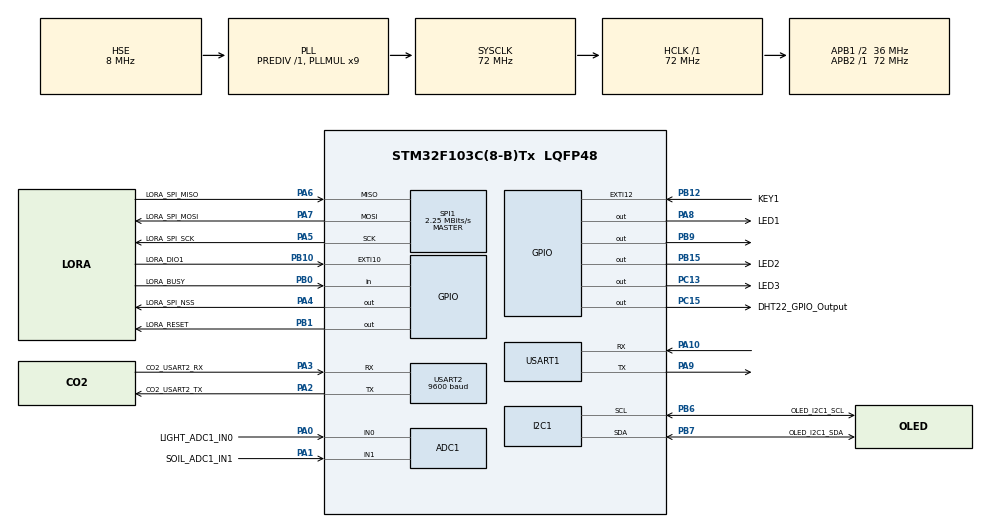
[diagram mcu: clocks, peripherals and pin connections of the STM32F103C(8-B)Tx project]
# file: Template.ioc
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ADC1.Channel-0\#ChannelRegularConversion=ADC_CHANNEL_0
ADC1.Channel-1\#ChannelRegularConversion=ADC_CHANNEL_1
ADC1.ContinuousConvMode=ENABLE
ADC1.NbrOfConversion=2
ADC1.NbrOfConversionFlag=1
ADC1.Rank-0\#ChannelRegularConversion=1
ADC1.Rank-1\#ChannelRegularConversion=2
ADC1.SamplingTime-0\#ChannelRegularConversion=ADC_SAMPLETIME_28CYCLES_5
ADC1.SamplingTime-1\#ChannelRegularConversion=ADC_SAMPLETIME_28CYCLES_5
ADC1.master=1
Dma.ADC1.0.Direction=DMA_PERIPH_TO_MEMORY
Dma.ADC1.0.Instance=DMA1_Channel1
Dma.ADC1.0.MemDataAlignment=DMA_MDATAALIGN_HALFWORD
Dma.ADC1.0.MemInc=DMA_MINC_ENABLE
Dma.ADC1.0.Mode=DMA_CIRCULAR
Dma.ADC1.0.PeriphDataAlignment=DMA_PDATAALIGN_HALFWORD
Dma.ADC1.0.PeriphInc=DMA_PINC_DISABLE
Dma.ADC1.0.Priority=DMA_PRIORITY_LOW
Dma.Request0=ADC1
Mcu.Family=STM32F1
Mcu.Name=STM32F103C(8-B)Tx
Mcu.Package=LQFP48
NVIC.DMA1_Channel1_IRQn=true\:0\:0\:false\:false\:true\:false\:true\:true
NVIC.EXTI15_10_IRQn=true\:0\:0\:true\:false\:true\:true\:true\:true
NVIC.PriorityGroup=NVIC_PRIORITYGROUP_4
NVIC.TIM3_IRQn=true\:0\:0\:false\:false\:true\:true\:true\:true
NVIC.USART1_IRQn=true\:0\:0\:false\:false\:true\:true\:true\:true
NVIC.USART2_IRQn=true\:0\:0\:false\:false\:true\:true\:true\:true
PA0-WKUP.GPIO_Label=LIGHT_ADC1_IN0
PA0-WKUP.Signal=ADCx_IN0
PA1.GPIO_Label=SOIL_ADC1_IN1
PA1.Signal=ADCx_IN1
PA10.Mode=Asynchronous
PA10.Signal=USART1_RX
PA13.Mode=Serial_Wire
PA13.Signal=SYS_JTMS-SWDIO
PA14.Mode=Serial_Wire
PA14.Signal=SYS_JTCK-SWCLK
PA2.GPIO_Label=CO2_USART2_TX
PA2.Mode=Asynchronous
PA2.Signal=USART2_TX
PA3.GPIO_Label=CO2_USART2_RX
PA3.Mode=Asynchronous
PA3.Signal=USART2_RX
PA4.GPIO_Label=LORA_SPI_NSS
PA4.GPIO_Speed=GPIO_SPEED_FREQ_HIGH
PA4.PinState=GPIO_PIN_SET
PA4.Signal=GPIO_Output
PA5.GPIO_Label=LORA_SPI_SCK
PA5.Mode=Full_Duplex_Master
PA5.Signal=SPI1_SCK
PA6.GPIO_Label=LORA_SPI_MISO
PA6.Mode=Full_Duplex_Master
PA6.Signal=SPI1_MISO
PA7.GPIO_Label=LORA_SPI_MOSI
PA7.Mode=Full_Duplex_Master
PA7.Signal=SPI1_MOSI
PA8.GPIO_Label=LED1
PA8.GPIO_PuPd=GPIO_PULLUP
PA8.PinState=GPIO_PIN_SET
PA8.Signal=GPIO_Output
PA9.Mode=Asynchronous
PA9.Signal=USART1_TX
PB0.GPIO_Label=LORA_BUSY
PB0.Signal=GPIO_Input
PB1.GPIO_Label=LORA_RESET
PB1.GPIO_Speed=GPIO_SPEED_FREQ_HIGH
PB1.PinState=GPIO_PIN_SET
PB1.Signal=GPIO_Output
PB10.GPIO_Label=LORA_DIO1
PB10.GPIO_ModeDefaultEXTI=GPIO_MODE_IT_RISING
PB10.Signal=GPXTI10
PB12.GPIO_Label=KEY1
PB12.GPIO_ModeDefaultEXTI=GPIO_MODE_IT_FALLING
PB12.GPIO_PuPd=GPIO_PULLUP
PB12.Signal=GPXTI12
PB15.GPIO_Label=LED2
PB15.GPIO_PuPd=GPIO_PULLUP
PB15.PinState=GPIO_PIN_SET
PB15.Signal=GPIO_Output
PB6.GPIO_Label=OLED_I2C1_SCL
PB6.GPIO_Pu=GPIO_PULLUP
PB6.Mode=I2C
PB6.Signal=I2C1_SCL
PB7.GPIO_Label=OLED_I2C1_SDA
PB7.GPIO_Pu=GPIO_PULLUP
PB7.Mode=I2C
PB7.Signal=I2C1_SDA
PB9.Signal=GPIO_Output
PC13-TAMPER-RTC.GPIO_Label=LED3
PC13-TAMPER-RTC.PinState=GPIO_PIN_SET
PC13-TAMPER-RTC.Signal=GPIO_Output
PC15-OSC32_OUT.GPIO_Label=DHT22_GPIO_Output
PC15-OSC32_OUT.GPIO_Speed=GPIO_SPEED_FREQ_MEDIUM
PC15-OSC32_OUT.PinState=GPIO_PIN_SET
PC15-OSC32_OUT.Signal=GPIO_Output
PD0-OSC_IN.Mode=HSE-External-Oscillator
PD0-OSC_IN.Signal=RCC_OSC_IN
PD1-OSC_OUT.Mode=HSE-External-Oscillator
PD1-OSC_OUT.Signal=RCC_OSC_OUT
ProjectManager.HeapSize=0x200
ProjectManager.StackSize=0x400
ProjectManager.TargetToolchain=MDK-ARM V5.27
RCC.ADCPresc=RCC_ADCPCLK2_DIV6
RCC.AHBFreq_Value=72000000
RCC.APB1CLKDivider=RCC_HCLK_DIV2
RCC.APB1Freq_Value=36000000
RCC.APB1TimFreq_Value=72000000
RCC.APB2Freq_Value=72000000
RCC.APB2TimFreq_Value=72000000
RCC.HCLKFreq_Value=72000000
RCC.PLLMUL=RCC_PLL_MUL9
RCC.PLLSourceVirtual=RCC_PLLSOURCE_HSE
RCC.SYSCLKFreq_VALUE=72000000
RCC.SYSCLKSource=RCC_SYSCLKSOURCE_PLLCLK
RCC.USBFreq_Value=72000000
SH.ADCx_IN0.0=ADC1_IN0,IN0
SH.ADCx_IN1.0=ADC1_IN1,IN1
SPI1.BaudRatePrescaler=SPI_BAUDRATEPRESCALER_32
SPI1.CalculateBaudRate=2.25 MBits/s
SPI1.Direction=SPI_DIRECTION_2LINES
SPI1.Mode=SPI_MODE_MASTER
SPI1.VirtualType=VM_MASTER
TIM1.AutoReloadPreload=TIM_AUTORELOAD_PRELOAD_ENABLE
TIM1.Period=999
TIM1.Prescaler=71
TIM3.AutoReloadPreload=TIM_AUTORELOAD_PRELOAD_ENABLE
TIM3.Period=999
TIM3.Prescaler=71
USART1.VirtualMode=VM_ASYNC
USART2.BaudRate=9600
USART2.VirtualMode=VM_ASYNC
VP_TIM1_VS_ClockSourceINT.Mode=Internal
VP_TIM3_VS_ClockSourceINT.Mode=Internal
board=custom

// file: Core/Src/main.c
#include "main.h"
#include "adc.h"
#include "dma.h"
#include "i2c.h"
#include "spi.h"
#include "tim.h"
#include "usart.h"
#include "gpio.h"

/* USER CODE BEGIN Includes */
#include "app_main.h"

/* USER CODE END Includes */

void SystemClock_Config(void);

int main(void)
{

  /* MCU Configuration--------------------------------------------------------*/

  /* Reset of all peripherals, Initializes the Flash interface and the Systick. */
  HAL_Init();

  /* Configure the system clock */
  SystemClock_Config();

  /* Initialize all configured peripherals */
  MX_GPIO_Init();
  MX_DMA_Init();
  MX_TIM3_Init();
  MX_TIM1_Init();
  MX_USART1_UART_Init();
  MX_USART2_UART_Init();
  MX_ADC1_Init();
  MX_I2C1_Init();
  MX_SPI1_Init();
  /* USER CODE BEGIN 2 */
  HAL_ADC_Start_DMA(&hadc1, (uint32_t *)adc1_values, 2);
	app_main();
  /* USER CODE END 2 */

  /* Infinite loop */
  while (1)
  {

  }
}

void SystemClock_Config(void)
{
  RCC_OscInitTypeDef RCC_OscInitStruct = {0};
  RCC_ClkInitTypeDef RCC_ClkInitStruct = {0};
  RCC_PeriphCLKInitTypeDef PeriphClkInit = {0};

  /** Initializes the RCC Oscillators according to the specified parameters
  * in the RCC_OscInitTypeDef structure.
  */
  RCC_OscInitStruct.OscillatorType = RCC_OSCILLATORTYPE_HSE;
  RCC_OscInitStruct.HSEState = RCC_HSE_ON;
  RCC_OscInitStruct.HSEPredivValue = RCC_HSE_PREDIV_DIV1;
  RCC_OscInitStruct.HSIState = RCC_HSI_ON;
  RCC_OscInitStruct.PLL.PLLState = RCC_PLL_ON;
  RCC_OscInitStruct.PLL.PLLSource = RCC_PLLSOURCE_HSE;
  RCC_OscInitStruct.PLL.PLLMUL = RCC_PLL_MUL9;
  if (HAL_RCC_OscConfig(&RCC_OscInitStruct) != HAL_OK)
  {
    Error_Handler();
  }

  /** Initializes the CPU, AHB and APB buses clocks
  */
  RCC_ClkInitStruct.ClockType = RCC_CLOCKTYPE_HCLK|RCC_CLOCKTYPE_SYSCLK
                              |RCC_CLOCKTYPE_PCLK1|RCC_CLOCKTYPE_PCLK2;
  RCC_ClkInitStruct.SYSCLKSource = RCC_SYSCLKSOURCE_PLLCLK;
  RCC_ClkInitStruct.AHBCLKDivider = RCC_SYSCLK_DIV1;
  RCC_ClkInitStruct.APB1CLKDivider = RCC_HCLK_DIV2;
  RCC_ClkInitStruct.APB2CLKDivider = RCC_HCLK_DIV1;

  if (HAL_RCC_ClockConfig(&RCC_ClkInitStruct, FLASH_LATENCY_2) != HAL_OK)
  {
    Error_Handler();
  }
  PeriphClkInit.PeriphClockSelection = RCC_PERIPHCLK_ADC;
  PeriphClkInit.AdcClockSelection = RCC_ADCPCLK2_DIV6;
  if (HAL_RCCEx_PeriphCLKConfig(&PeriphClkInit) != HAL_OK)
  {
    Error_Handler();
  }
}

void Error_Handler(void)
{
  __disable_irq();
  while (1)
  {
  }
}
